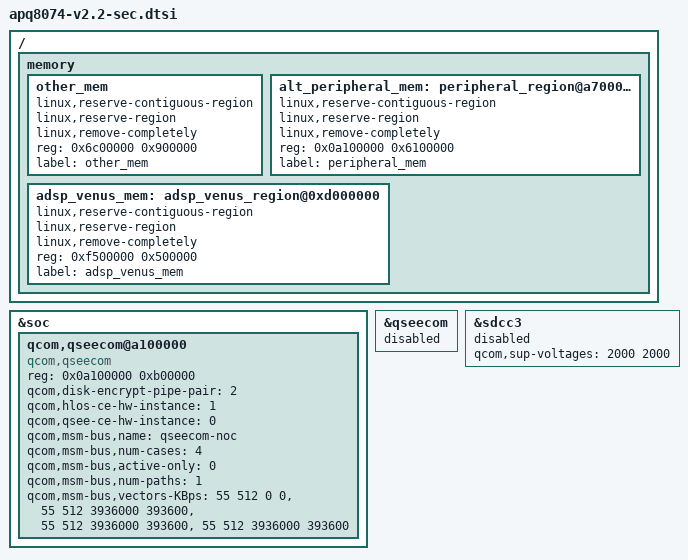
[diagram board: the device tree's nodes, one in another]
/* Copyright (c) 2013, The Linux Foundation. All rights reserved.
 *
 * This program is free software; you can redistribute it and/or modify
 * it under the terms of the GNU General Public License version 2 and
 * only version 2 as published by the Free Software Foundation.
 *
 * This program is distributed in the hope that it will be useful,
 * but WITHOUT ANY WARRANTY; without even the implied warranty of
 * MERCHANTABILITY or FITNESS FOR A PARTICULAR PURPOSE.  See the
 * GNU General Public License for more details.
 */

/*
 * As a general rule, only version-specific property overrides should be placed
 * inside this file. However, device definitions should be placed inside the
 * msm8974.dtsi file.
 */

/include/ "msm8974-v2.2-sec.dtsi"
/include/ "apq8074-v2.2-ion.dtsi"

/ {
        memory {
		/* Samsung added this memory hole but it's not clear to me
		 * what it is used for.  Carve it out for whatever magic needs it */
		other_mem {
			linux,reserve-contiguous-region;
			linux,reserve-region;
			linux,remove-completely;
                        reg = <0x6c00000 0x900000>;
			label = "other_mem";
		};

                alt_peripheral_mem: peripheral_region@a700000 {
			linux,reserve-contiguous-region;
			linux,reserve-region;
			linux,remove-completely;
                        reg = <0x0a100000 0x6100000>;
			label = "peripheral_mem";
		};

		adsp_venus_mem: adsp_venus_region@0xd000000 {
			linux,reserve-contiguous-region;
			linux,reserve-region;
			linux,remove-completely;
                        reg = <0xf500000 0x500000>;
			label = "adsp_venus_mem";

		};
        };
};

&soc {
	qcom,qseecom@a100000 {
		compatible = "qcom,qseecom";
		reg = <0x0a100000 0xb00000>;
		reg-names = "secapp-region";
		qcom,disk-encrypt-pipe-pair = <2>;
		qcom,hlos-ce-hw-instance = <1>;
		qcom,qsee-ce-hw-instance = <0>;
		qcom,msm-bus,name = "qseecom-noc";
		qcom,msm-bus,num-cases = <4>;
		qcom,msm-bus,active-only = <0>;
		qcom,msm-bus,num-paths = <1>;
		qcom,msm-bus,vectors-KBps =
				<55 512 0 0>,
				<55 512 3936000 393600>,
				<55 512 3936000 393600>,
				<55 512 3936000 393600>;
	};
};

&qseecom {
	status = "disabled";
};

&sdcc3 {
	qcom,sup-voltages = <2000 2000>;
	status = "disabled";
};

